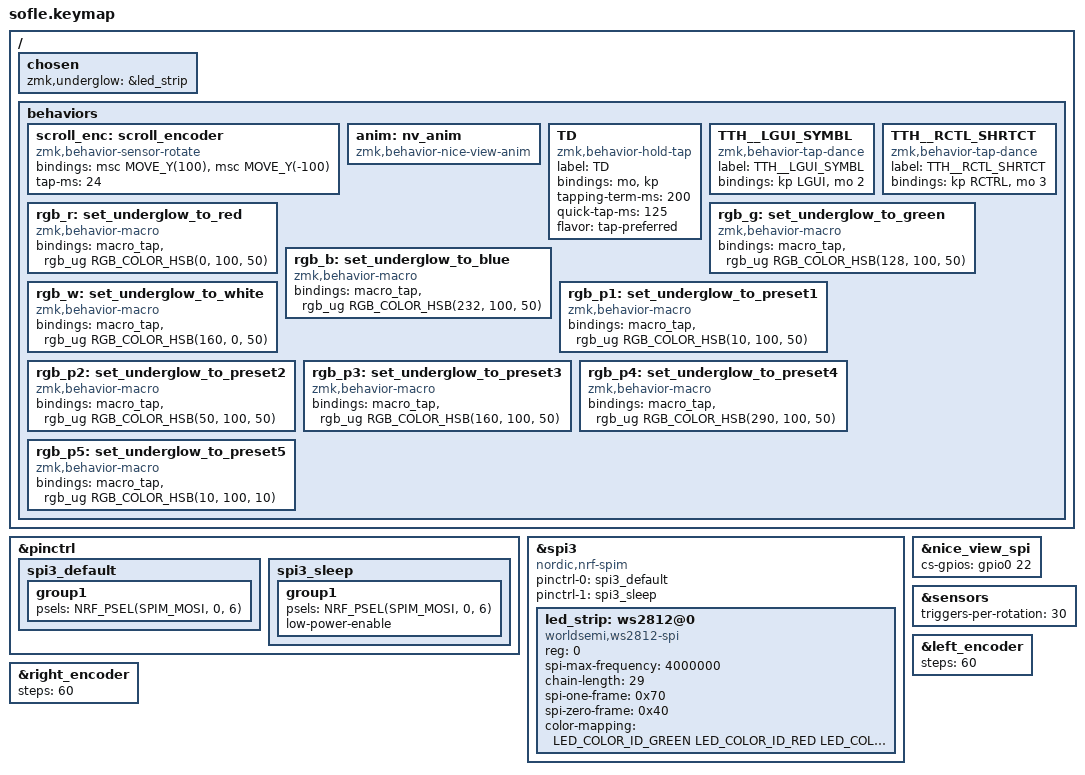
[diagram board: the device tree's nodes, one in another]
/*
 * Copyright (c) 2020 The ZMK Contributors
 *
 * SPDX-License-Identifier: MIT
 */

#include <behaviors.dtsi>  // https://zmk.dev/docs/development/new-behavior
#include <dt-bindings/zmk/keys.h>  // https://zmk.dev/docs/keymaps
#include <dt-bindings/zmk/bt.h>  // https://zmk.dev/docs/keymaps/behaviors/bluetooth
#include <dt-bindings/zmk/rgb.h>  // https://zmk.dev/docs/keymaps/behaviors/underglow
#include <dt-bindings/zmk/ext_power.h>  // https://zmk.dev/docs/keymaps/behaviors/power
#include <dt-bindings/zmk/outputs.h>  // https://zmk.dev/docs/keymaps/behaviors/outputs
#include <dt-bindings/led/led.h>  // https://zmk.dev/docs/features/underglow
#include <dt-bindings/zmk/rgb_layer_colors.h>  // fork : effet "couleurs par layer" (RGB_TRANS)
#include <dt-bindings/zmk/nice_view_anim.h>  // fork nice-view-gem : &anim (animations de l'écran)
#include <dt-bindings/zmk/pointing.h>  // https://zmk.dev/docs/keymaps/behaviors/mouse-emulation (&msc, MOVE_Y)

&pinctrl {
    spi3_default: spi3_default {
        group1 {
            psels = <NRF_PSEL(SPIM_MOSI, 0, 6)>;
        };
    };

    spi3_sleep: spi3_sleep {
        group1 {
            psels = <NRF_PSEL(SPIM_MOSI, 0, 6)>;
            low-power-enable;
        };
    };
};

&spi3 {
    compatible = "nordic,nrf-spim";
    status = "okay";

    pinctrl-0 = <&spi3_default>;
    pinctrl-1 = <&spi3_sleep>;
    pinctrl-names = "default", "sleep";

    led_strip: ws2812@0 {
        compatible = "worldsemi,ws2812-spi";

        /* SPI */
        reg = <0>; /* ignored, but necessary for SPI bindings */
        spi-max-frequency = <4000000>;

        /* WS2812 */
        chain-length = <29>; /* arbitrary; change at will */
        spi-one-frame = <0x70>;
        spi-zero-frame = <0x40>;

        color-mapping = <
            LED_COLOR_ID_GREEN
            LED_COLOR_ID_RED
            LED_COLOR_ID_BLUE
        >;
    };
};

/ {
    chosen {
        zmk,underglow = &led_strip;
    };
};



&nice_view_spi {
    cs-gpios = <&gpio0 22 GPIO_ACTIVE_HIGH>;
};




#define BASE 0
#define SETTINGS 1
#define SYMBOLS 2
#define SHORTCUTS 3
#define NUMPAD 4
#define EXTRAS 5
#define BOARD 6

// &led_strip { chain-length = <29>; };
&sensors { triggers-per-rotation = <30>; };
// Encodeurs 30 crans / 15 impulsions : 2 transitions par cran -> 60 par tour
// (le shield déclare 80, ce qui faisait ignorer un cran sur deux par moments).
&left_encoder  { steps = <60>; };
&right_encoder { steps = <60>; };

/ {
    behaviors {
        // Encodeur droit = molette de souris : 1 cran d'encodeur -> 1 cran de molette.
        // &msc avance toutes les 16 ms de vitesse x 16 / 1000 crans, le reste est perdu
        // au relâchement : vitesse 100 -> 1,6 -> 1 cran ; tap-ms 24 -> un seul pas.
        // Sens horaire = défilement vers le haut (comme l'ancien C_AC_SCROLL_UP).
        scroll_enc: scroll_encoder {
            compatible = "zmk,behavior-sensor-rotate";
            #sensor-binding-cells = <0>;
            bindings = <&msc MOVE_Y(100)>, <&msc MOVE_Y(-100)>;
            tap-ms = <24>;
        };

        // Animations de l'écran droit : ANIM_NXT, ANIM_PRV, ANIM_SEL n, ANIM_TOG (fixe/animé)
        anim: nv_anim {
            compatible = "zmk,behavior-nice-view-anim";
            #binding-cells = <2>;
        };
        TD: TD {
            compatible = "zmk,behavior-hold-tap";
            label = "TD";
            bindings = <&mo>, <&kp>;
            #binding-cells = <2>;
            tapping-term-ms = <200>;
			quick-tap-ms = <125>;
            flavor = "tap-preferred";
        };

        TTH__LGUI_SYMBL: TTH__LGUI_SYMBL {
            compatible = "zmk,behavior-tap-dance";
            label = "TTH__LGUI_SYMBL";
            #binding-cells = <0>;
            bindings = <&kp LGUI>, <&mo 2>;
        };

        TTH__RCTL_SHRTCT: TTH__RCTL_SHRTCT {
            compatible = "zmk,behavior-tap-dance";
            label = "TTH__RCTL_SHRTCT";
            #binding-cells = <0>;
            bindings = <&kp RCTRL>, <&mo 3>;
        };
		
		rgb_r: set_underglow_to_red {
            compatible = "zmk,behavior-macro";
            #binding-cells = <0>;
            bindings
                = <&macro_tap &rgb_ug RGB_COLOR_HSB(0, 100, 50)>;
		};
		
		rgb_g: set_underglow_to_green {
            compatible = "zmk,behavior-macro";
            #binding-cells = <0>;
            bindings
                = <&macro_tap &rgb_ug RGB_COLOR_HSB(128, 100, 50)>;
		};
		
		rgb_b: set_underglow_to_blue {
            compatible = "zmk,behavior-macro";
            #binding-cells = <0>;
            bindings
                = <&macro_tap &rgb_ug RGB_COLOR_HSB(232, 100, 50)>;
		};
		
		rgb_w: set_underglow_to_white {
            compatible = "zmk,behavior-macro";
            #binding-cells = <0>;
            bindings
                = <&macro_tap &rgb_ug RGB_COLOR_HSB(160, 0, 50)>;
		};
		
		rgb_p1: set_underglow_to_preset1 {
            compatible = "zmk,behavior-macro";
            #binding-cells = <0>;
            bindings
                = <&macro_tap &rgb_ug RGB_COLOR_HSB(10, 100, 50)>;
		};
		
		rgb_p2: set_underglow_to_preset2 {
            compatible = "zmk,behavior-macro";
            #binding-cells = <0>;
            bindings
                = <&macro_tap &rgb_ug RGB_COLOR_HSB(50, 100, 50)>;
		};
		
		rgb_p3: set_underglow_to_preset3 {
            compatible = "zmk,behavior-macro";
            #binding-cells = <0>;
            bindings
                = <&macro_tap &rgb_ug RGB_COLOR_HSB(160, 100, 50)>;
		};
		
		rgb_p4: set_underglow_to_preset4 {
            compatible = "zmk,behavior-macro";
            #binding-cells = <0>;
            bindings
                = <&macro_tap &rgb_ug RGB_COLOR_HSB(290, 100, 50)>;
		};
		
		rgb_p5: set_underglow_to_preset5 {
            compatible = "zmk,behavior-macro";
            #binding-cells = <0>;
            bindings
                = <&macro_tap &rgb_ug RGB_COLOR_HSB(10, 100, 10)>;
		};
    };



    // Couleurs par layer (effet RGB 4) : voir sofle_colors.dtsi
#include "sofle_colors.dtsi"

    // Mapping des touches (7 layers) : voir sofle_layers.dtsi
#include "sofle_layers.dtsi"
};
